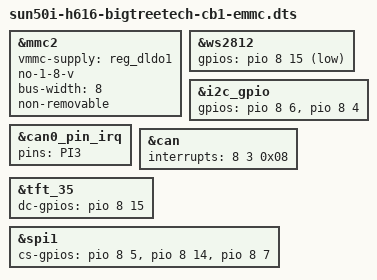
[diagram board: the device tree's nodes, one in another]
// SPDX-License-Identifier: (GPL-2.0+ or MIT)
/*
 * Copyright (C) 2023 Alan.Ma <tech@biqu3d.com>.
 */

/dts-v1/;

#include "sun50i-h616-bigtreetech-cb1.dtsi"

&mmc2 {
	vmmc-supply = <&reg_dldo1>;

	no-1-8-v;
	bus-width = <8>;
	non-removable;
	status = "okay";
};

&ws2812 {
	gpios = <&pio 8 15 GPIO_ACTIVE_LOW>; /* PI15 */
};

&i2c_gpio {
	gpios = <&pio 8 6 (GPIO_ACTIVE_HIGH | GPIO_OPEN_DRAIN)>, /* SDA PI6 */
			<&pio 8 4 (GPIO_ACTIVE_HIGH | GPIO_OPEN_DRAIN)>; /* SCL PI4 */
};

&can0_pin_irq {
	pins = "PI3";
};

&can {
	interrupts = <8 3 0x08>; /* PI3 IRQ_TYPE_LEVEL_LOW */
};

&tft_35 {
	dc-gpios  = <&pio 8 15 GPIO_ACTIVE_HIGH>; /* PI15 */
};

&spi1 {
	cs-gpios = <&pio 8 5 GPIO_ACTIVE_HIGH>, /* PI5 */
			   <&pio 8 14 GPIO_ACTIVE_HIGH>, /* PI14 */
			   <&pio 8 7 GPIO_ACTIVE_HIGH>; /* PI7 */
};
